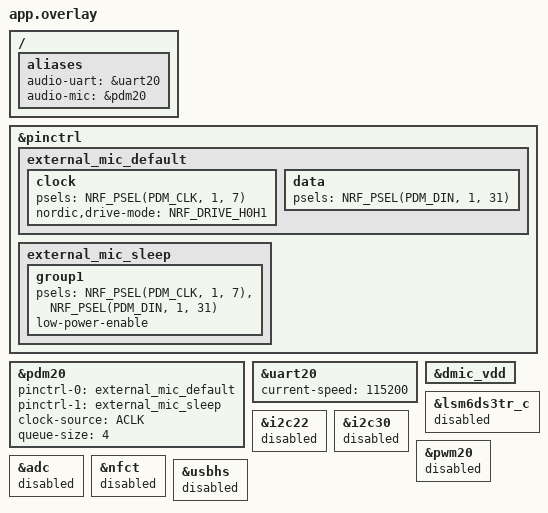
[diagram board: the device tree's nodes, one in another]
#include <zephyr/dt-bindings/pinctrl/nrf-pinctrl.h>

/ {
	aliases {
		audio-uart = &uart20;
		audio-mic = &pdm20;
	};
};

&pinctrl {
	external_mic_default: external_mic_default {
		clock {
			psels = <NRF_PSEL(PDM_CLK, 1, 7)>; /* XIAO D5 -> mic CLOCK; clock-capable pad */
			nordic,drive-mode = <NRF_DRIVE_H0H1>;
		};
		data {
			psels = <NRF_PSEL(PDM_DIN, 1, 31)>; /* XIAO D1 <- mic DATA */
		};
	};
	external_mic_sleep: external_mic_sleep {
		group1 {
			psels = <NRF_PSEL(PDM_CLK, 1, 7)>, <NRF_PSEL(PDM_DIN, 1, 31)>;
			low-power-enable;
		};
	};
};

&pdm20 {
	status = "okay";
	pinctrl-0 = <&external_mic_default>;
	pinctrl-1 = <&external_mic_sleep>;
	pinctrl-names = "default", "sleep";
	/* LM20A ACLK is FIXED 24 MHz, not a configurable audio PLL. */
	clock-source = "ACLK";
	queue-size = <4>;
};

&uart20 {
	status = "okay";
	current-speed = <115200>;
};

/* External mic uses the XIAO 3V3 pin. Leave onboard sensor power off. */
&dmic_vdd {
	/delete-property/ regulator-boot-on;
};
&lsm6ds3tr_c { status = "disabled"; };
/* I2C22 otherwise claims P1.07 as SCL. PMIC uses separate gpio-i2c. */
&i2c22 { status = "disabled"; };
&i2c30 { status = "disabled"; };
&pwm20 { status = "disabled"; };
&adc { status = "disabled"; };
&nfct { status = "disabled"; };
&usbhs { status = "disabled"; };

